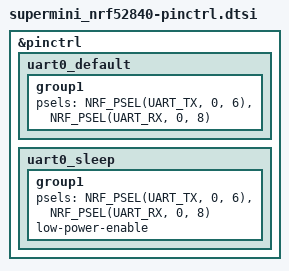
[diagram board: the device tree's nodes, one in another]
/*
 * Pin control for SuperMini nRF52840.
 * UART0: TX=P0.06 on header D1, RX=P0.08 on header D0 (as on Nice!Nano v2).
 */

&pinctrl {
	uart0_default: uart0_default {
		group1 {
			psels = <NRF_PSEL(UART_TX, 0, 6)>,
				<NRF_PSEL(UART_RX, 0, 8)>;
		};
	};

	uart0_sleep: uart0_sleep {
		group1 {
			psels = <NRF_PSEL(UART_TX, 0, 6)>,
				<NRF_PSEL(UART_RX, 0, 8)>;
			low-power-enable;
		};
	};
};
